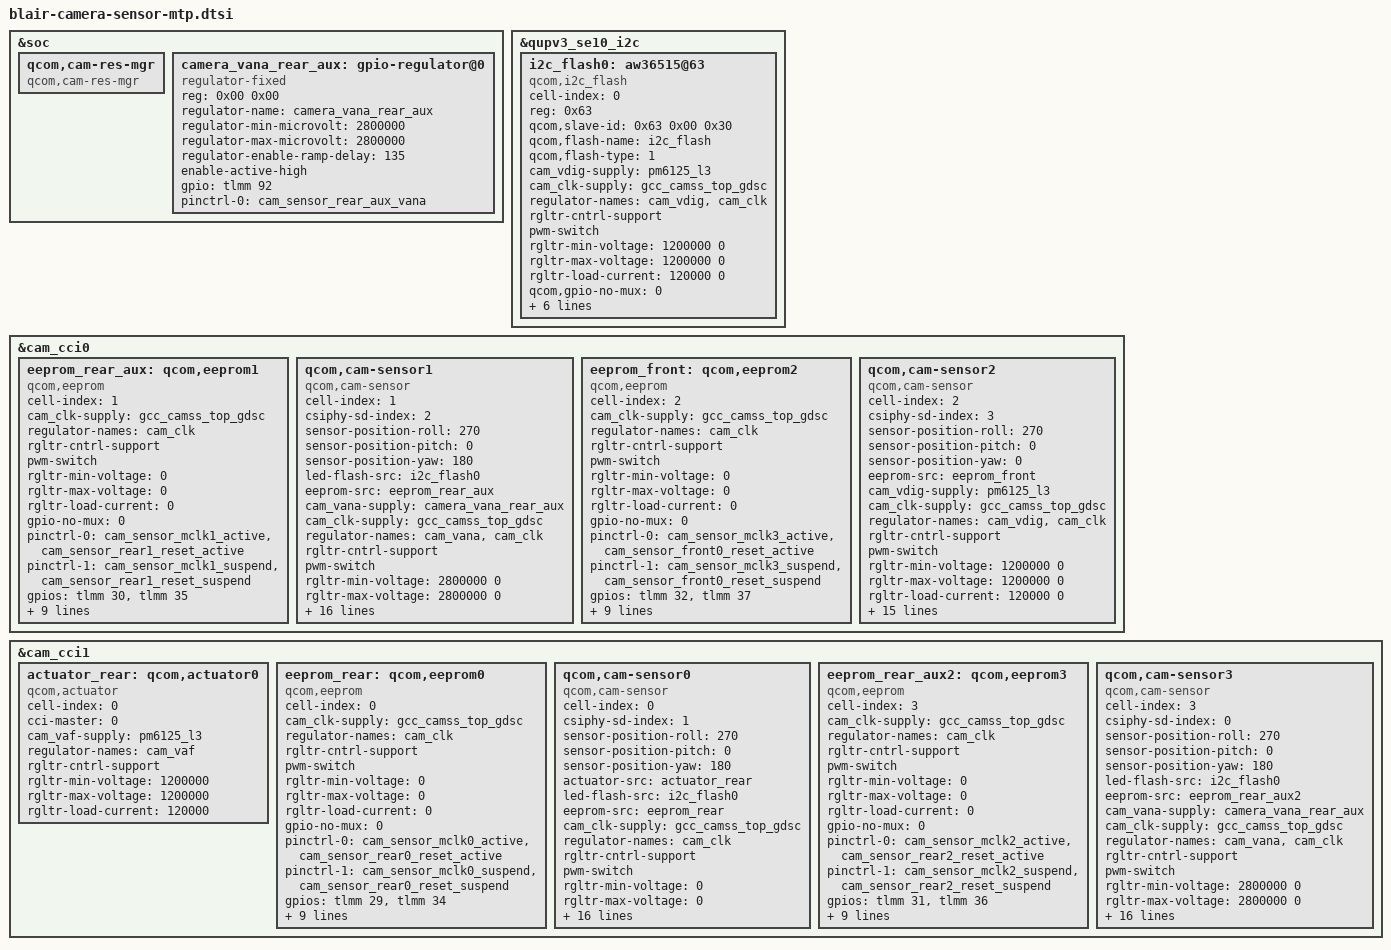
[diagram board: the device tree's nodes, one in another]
#include <dt-bindings/clock/qcom,gcc-blair.h>
#include <dt-bindings/msm/msm-camera.h>
&soc {

	qcom,cam-res-mgr {
		compatible = "qcom,cam-res-mgr";
		status = "ok";
	};

	camera_vana_rear_aux: gpio-regulator@0 {
		compatible = "regulator-fixed";
		reg = <0x00 0x00>;
		regulator-name = "camera_vana_rear_aux";
		regulator-min-microvolt = <2800000>;
		regulator-max-microvolt = <2800000>;
		regulator-enable-ramp-delay = <135>;
		enable-active-high;
		gpio = <&tlmm 92 0>;
		pinctrl-names = "default";
		pinctrl-0 = <&cam_sensor_rear_aux_vana>;
	};
};

&qupv3_se10_i2c {
		status = "ok";
		i2c_flash0:aw36515@63 {
			cell-index = <0>;
			compatible = "qcom,i2c_flash";
			reg = <0x63>;
			status = "ok";
			qcom,slave-id = <0x63 0x00 0x30>;
			qcom,flash-name = "i2c_flash";
			qcom,flash-type = <1>;
			cam_vdig-supply = <&pm6125_l3>;
			cam_clk-supply = <&gcc_camss_top_gdsc>;
			regulator-names = "cam_vdig", "cam_clk";
			rgltr-cntrl-support;
			pwm-switch;
			rgltr-min-voltage = <1200000 0>;
			rgltr-max-voltage = <1200000 0>;
			rgltr-load-current = <120000 0>;
			qcom,gpio-no-mux = <0>;
			gpios = <&tlmm 107 0>,
				  <&tlmm 51 0>;
			qcom,gpio-flash-en = <0>;
			qcom,gpio-flash-now = <1>;
			gpio-req-tbl-num = <0 1>;
			gpio-req-tbl-flags = <0 0>;
			gpio-req-tbl-label = "FLASH_EN",
                            "FLASH_NOW";
		};
};

&cam_cci0 {

	eeprom_rear_aux: qcom,eeprom1 {
		cell-index = <1>;
		compatible = "qcom,eeprom";
		cam_clk-supply = <&gcc_camss_top_gdsc>;
		regulator-names = "cam_clk";
		rgltr-cntrl-support;
		pwm-switch;
		rgltr-min-voltage = <0>;
		rgltr-max-voltage = <0>;
		rgltr-load-current = <0>;
		gpio-no-mux = <0>;
		pinctrl-names = "cam_default", "cam_suspend";
		pinctrl-0 = <&cam_sensor_mclk1_active
                 &cam_sensor_rear1_reset_active>;
		pinctrl-1 = <&cam_sensor_mclk1_suspend
                 &cam_sensor_rear1_reset_suspend>;
		gpios = <&tlmm 30 0>,
			<&tlmm 35 0>;
		gpio-reset = <1>;
		gpio-req-tbl-num = <0 1>;
		gpio-req-tbl-flags = <1 0>;
		gpio-req-tbl-label = "CAMIF_MCLK1",
                         "CAM_RESET1";
		sensor-mode = <0>;
		cci-master = <0>;
		status = "ok";
		clocks = <&gcc GCC_CAMSS_MCLK1_CLK>;
		clock-names = "cam_clk";
		clock-cntl-level = "turbo";
		clock-rates = <24000000>;
	};

	/*Rear Aux*/
	qcom,cam-sensor1 {
		cell-index = <1>;
		compatible = "qcom,cam-sensor";
		csiphy-sd-index = <2>;
		sensor-position-roll = <270>;
		sensor-position-pitch = <0>;
		sensor-position-yaw = <180>;
		led-flash-src = <&i2c_flash0>;
		eeprom-src = <&eeprom_rear_aux>;
		cam_vana-supply = <&camera_vana_rear_aux>;
		cam_clk-supply = <&gcc_camss_top_gdsc>;
		regulator-names = "cam_vana", "cam_clk";
		rgltr-cntrl-support;
		pwm-switch;
		rgltr-min-voltage = <2800000 0>;
		rgltr-max-voltage = <2800000 0>;
		rgltr-load-current = <80000 0>;
		gpio-no-mux = <0>;
		pinctrl-names = "cam_default", "cam_suspend";
		pinctrl-0 = <&cam_sensor_mclk1_active
                 &cam_sensor_rear1_reset_active>;
		pinctrl-1 = <&cam_sensor_mclk1_suspend
                 &cam_sensor_rear1_reset_suspend>;
		gpios = <&tlmm 30 0>,
			<&tlmm 35 0>;
		gpio-reset = <1>;
		gpio-req-tbl-num = <0 1>;
		gpio-req-tbl-flags = <1 0>;
		gpio-req-tbl-label = "CAMIF_MCLK1",
                         "CAM_RESET1";
		sensor-mode = <0>;
		cci-master = <0>;
		status = "ok";
		clocks = <&gcc GCC_CAMSS_MCLK1_CLK>;
		clock-names = "cam_clk";
		clock-cntl-level = "turbo";
		clock-rates = <24000000>;
	};

	eeprom_front: qcom,eeprom2 {
		cell-index = <2>;
		compatible = "qcom,eeprom";
		cam_clk-supply = <&gcc_camss_top_gdsc>;
		regulator-names = "cam_clk";
		rgltr-cntrl-support;
		pwm-switch;
		rgltr-min-voltage = <0>;
		rgltr-max-voltage = <0>;
		rgltr-load-current = <0>;
		gpio-no-mux = <0>;
		pinctrl-names = "cam_default", "cam_suspend";
		pinctrl-0 = <&cam_sensor_mclk3_active
                 &cam_sensor_front0_reset_active>;
		pinctrl-1 = <&cam_sensor_mclk3_suspend
                 &cam_sensor_front0_reset_suspend>;
		gpios = <&tlmm 32 0>,
			<&tlmm 37 0>;
		gpio-reset = <1>;
		gpio-req-tbl-num = <0 1>;
		gpio-req-tbl-flags = <1 0>;
		gpio-req-tbl-label = "CAMIF_MCLK3",
                         "CAM_RESET3";
		sensor-mode = <0>;
		cci-master = <1>;
		status = "ok";
		clocks = <&gcc GCC_CAMSS_MCLK3_CLK>;
		clock-names = "cam_clk";
		clock-cntl-level = "turbo";
		clock-rates = <24000000>;
	};

  /*Front*/
	qcom,cam-sensor2 {
		cell-index = <2>;
		compatible = "qcom,cam-sensor";
		csiphy-sd-index = <3>;
		sensor-position-roll = <270>;
		sensor-position-pitch = <0>;
		sensor-position-yaw = <0>;
		eeprom-src = <&eeprom_front>;
		cam_vdig-supply = <&pm6125_l3>;
		cam_clk-supply = <&gcc_camss_top_gdsc>;
		regulator-names = "cam_vdig", "cam_clk";
		rgltr-cntrl-support;
		pwm-switch;
		rgltr-min-voltage = <1200000 0>;
		rgltr-max-voltage = <1200000 0>;
		rgltr-load-current = <120000 0>;
		gpio-no-mux = <0>;
		pinctrl-names = "cam_default", "cam_suspend";
		pinctrl-0 = <&cam_sensor_mclk3_active
                 &cam_sensor_front0_reset_active>;
		pinctrl-1 = <&cam_sensor_mclk3_suspend
                 &cam_sensor_front0_reset_suspend>;
		gpios = <&tlmm 32 0>,
			  <&tlmm 37 0>;
		gpio-reset = <1>;
		gpio-req-tbl-num = <0 1>;
		gpio-req-tbl-flags = <1 0>;
		gpio-req-tbl-label = "CAMIF_MCLK3",
                         "CAM_RESET3";
		sensor-mode = <0>;
		cci-master = <1>;
		status = "ok";
		clocks = <&gcc GCC_CAMSS_MCLK3_CLK>;
		clock-names = "cam_clk";
		clock-cntl-level = "turbo";
		clock-rates = <24000000>;
	};
};

&cam_cci1 {
	actuator_rear: qcom,actuator0 {
		cell-index = <0>;
		compatible = "qcom,actuator";
		cci-master= <0>;
		cam_vaf-supply = <&pm6125_l3>;
		regulator-names = "cam_vaf";
		rgltr-cntrl-support;
		rgltr-min-voltage = <1200000>;
		rgltr-max-voltage = <1200000>;
		rgltr-load-current = <120000>;
		status = "ok";
	};

	eeprom_rear: qcom,eeprom0 {
		cell-index = <0>;
		compatible = "qcom,eeprom";
		cam_clk-supply = <&gcc_camss_top_gdsc>;
		regulator-names = "cam_clk";
		rgltr-cntrl-support;
		pwm-switch;
		rgltr-min-voltage = <0>;
		rgltr-max-voltage = <0>;
		rgltr-load-current = <0>;
		gpio-no-mux = <0>;
		pinctrl-names = "cam_default", "cam_suspend";
		pinctrl-0 = <&cam_sensor_mclk0_active
                 &cam_sensor_rear0_reset_active>;
		pinctrl-1 = <&cam_sensor_mclk0_suspend
                 &cam_sensor_rear0_reset_suspend>;
		gpios = <&tlmm 29 0>,
			  <&tlmm 34 0>;
		gpio-reset = <1>;
		gpio-req-tbl-num = <0 1>;
		gpio-req-tbl-flags = <1 0>;
		gpio-req-tbl-label = "CAMIF_MCLK0",
                         "CAM_RESET0";
		sensor-mode = <0>;
		cci-master = <0>;
		status = "ok";
		clocks = <&gcc GCC_CAMSS_MCLK0_CLK>;
		clock-names = "cam_clk";
		clock-cntl-level = "turbo";
		clock-rates = <24000000>;
	};

    /* Rear*/
	qcom,cam-sensor0 {
		cell-index = <0>;
		compatible = "qcom,cam-sensor";
		csiphy-sd-index = <1>;
		sensor-position-roll = <270>;
		sensor-position-pitch = <0>;
		sensor-position-yaw = <180>;
		actuator-src = <&actuator_rear>;
		led-flash-src = <&i2c_flash0>;
		eeprom-src = <&eeprom_rear>;
		cam_clk-supply = <&gcc_camss_top_gdsc>;
		regulator-names = "cam_clk";
		rgltr-cntrl-support;
		pwm-switch;
		rgltr-min-voltage = <0>;
		rgltr-max-voltage = <0>;
		rgltr-load-current = <0>;
		gpio-no-mux = <0>;
		pinctrl-names = "cam_default", "cam_suspend";
		pinctrl-0 = <&cam_sensor_mclk0_active
                &cam_sensor_rear0_reset_active>;
		pinctrl-1 = <&cam_sensor_mclk0_suspend
                &cam_sensor_rear0_reset_suspend>;
		gpios = <&tlmm 29 0>,
			  <&tlmm 34 0>;
		gpio-reset = <1>;
		gpio-req-tbl-num = <0 1>;
		gpio-req-tbl-flags = <1 0>;
		gpio-req-tbl-label = "CAMIF_MCLK0",
					"CAM_RESET0";
		sensor-mode = <0>;
		cci-master = <0>;
		status = "ok";
		clocks = <&gcc GCC_CAMSS_MCLK0_CLK>;
		clock-names = "cam_clk";
		clock-cntl-level = "turbo";
		clock-rates = <24000000>;
	};

	eeprom_rear_aux2: qcom,eeprom3 {
		cell-index = <3>;
		compatible = "qcom,eeprom";
		cam_clk-supply = <&gcc_camss_top_gdsc>;
		regulator-names = "cam_clk";
		rgltr-cntrl-support;
		pwm-switch;
		rgltr-min-voltage = <0>;
		rgltr-max-voltage = <0>;
		rgltr-load-current = <0>;
		gpio-no-mux = <0>;
		pinctrl-names = "cam_default", "cam_suspend";
		pinctrl-0 = <&cam_sensor_mclk2_active
                &cam_sensor_rear2_reset_active>;
		pinctrl-1 = <&cam_sensor_mclk2_suspend
                &cam_sensor_rear2_reset_suspend>;
		gpios = <&tlmm 31 0>,
			<&tlmm 36 0>;
		gpio-reset = <1>;
		gpio-req-tbl-num = <0 1>;
		gpio-req-tbl-flags = <1 0>;
		gpio-req-tbl-label = "CAMIF_MCLK2",
                         "CAM_RESET2";
		sensor-mode = <0>;
		cci-master = <0>;
		status = "ok";
		clocks = <&gcc GCC_CAMSS_MCLK2_CLK>;
		clock-names = "cam_clk";
		clock-cntl-level = "turbo";
		clock-rates = <24000000>;
	};

	/*Rear Aux2*/
	qcom,cam-sensor3 {
		cell-index = <3>;
		compatible = "qcom,cam-sensor";
		csiphy-sd-index = <0>;
		sensor-position-roll = <270>;
		sensor-position-pitch = <0>;
		sensor-position-yaw = <180>;
		led-flash-src = <&i2c_flash0>;
		eeprom-src = <&eeprom_rear_aux2>;
		cam_vana-supply = <&camera_vana_rear_aux>;
		cam_clk-supply = <&gcc_camss_top_gdsc>;
		regulator-names = "cam_vana", "cam_clk";
		rgltr-cntrl-support;
		pwm-switch;
		rgltr-min-voltage = <2800000 0>;
		rgltr-max-voltage = <2800000 0>;
		rgltr-load-current = <80000 0>;
		gpio-no-mux = <0>;
		pinctrl-names = "cam_default", "cam_suspend";
		pinctrl-0 = <&cam_sensor_mclk2_active
                &cam_sensor_rear2_reset_active>;
		pinctrl-1 = <&cam_sensor_mclk2_suspend
                &cam_sensor_rear2_reset_suspend>;
		gpios = <&tlmm 31 0>,
			  <&tlmm 36 0>;
		gpio-reset = <1>;
		gpio-req-tbl-num = <0 1>;
		gpio-req-tbl-flags = <1 0>;
		gpio-req-tbl-label = "CAMIF_MCLK2",
                         "CAM_RESET2";
		sensor-mode = <0>;
		cci-master = <0>;
		status = "ok";
		clocks = <&gcc GCC_CAMSS_MCLK2_CLK>;
		clock-names = "cam_clk";
		clock-cntl-level = "turbo";
		clock-rates = <24000000>;
	};
};
